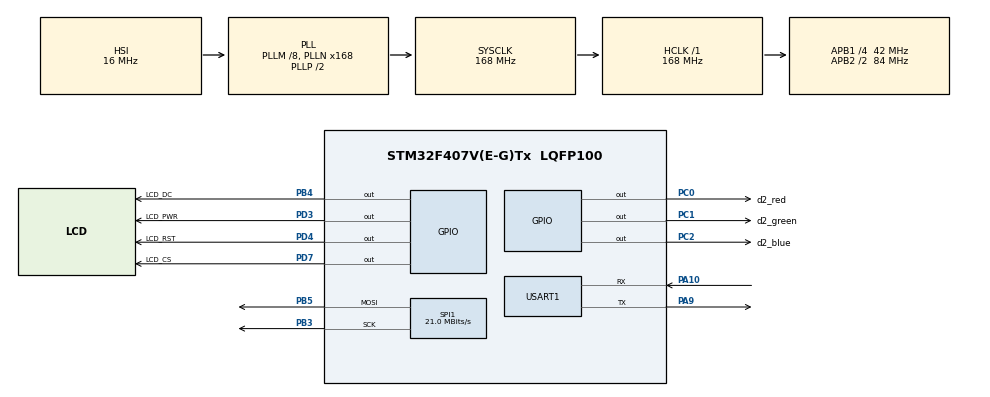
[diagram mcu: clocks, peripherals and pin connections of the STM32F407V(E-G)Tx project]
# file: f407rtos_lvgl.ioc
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Dma.Request0=USART1_RX
Dma.Request1=USART1_TX
Dma.USART1_RX.0.Direction=DMA_PERIPH_TO_MEMORY
Dma.USART1_RX.0.FIFOMode=DMA_FIFOMODE_DISABLE
Dma.USART1_RX.0.Instance=DMA2_Stream2
Dma.USART1_RX.0.MemDataAlignment=DMA_MDATAALIGN_BYTE
Dma.USART1_RX.0.MemInc=DMA_MINC_ENABLE
Dma.USART1_RX.0.Mode=DMA_NORMAL
Dma.USART1_RX.0.PeriphDataAlignment=DMA_PDATAALIGN_BYTE
Dma.USART1_RX.0.PeriphInc=DMA_PINC_DISABLE
Dma.USART1_RX.0.Priority=DMA_PRIORITY_LOW
Dma.USART1_TX.1.Direction=DMA_MEMORY_TO_PERIPH
Dma.USART1_TX.1.FIFOMode=DMA_FIFOMODE_DISABLE
Dma.USART1_TX.1.Instance=DMA2_Stream7
Dma.USART1_TX.1.MemDataAlignment=DMA_MDATAALIGN_BYTE
Dma.USART1_TX.1.MemInc=DMA_MINC_ENABLE
Dma.USART1_TX.1.Mode=DMA_NORMAL
Dma.USART1_TX.1.PeriphDataAlignment=DMA_PDATAALIGN_BYTE
Dma.USART1_TX.1.PeriphInc=DMA_PINC_DISABLE
Dma.USART1_TX.1.Priority=DMA_PRIORITY_LOW
IWDG.Prescaler=IWDG_PRESCALER_64
IWDG.Reload=1000
Mcu.Family=STM32F4
Mcu.Name=STM32F407V(E-G)Tx
Mcu.Package=LQFP100
NVIC.DMA2_Stream2_IRQn=true\:6\:0\:true\:false\:true\:false\:true\:true
NVIC.DMA2_Stream7_IRQn=true\:8\:0\:true\:false\:true\:false\:true\:true
NVIC.PriorityGroup=NVIC_PRIORITYGROUP_4
NVIC.TIM2_IRQn=true\:0\:0\:false\:false\:true\:true\:true\:true
NVIC.USART1_IRQn=true\:6\:0\:true\:false\:true\:true\:true\:true
PA10.Mode=Asynchronous
PA10.Signal=USART1_RX
PA13.Mode=Serial_Wire
PA13.Signal=SYS_JTMS-SWDIO
PA14.Mode=Serial_Wire
PA14.Signal=SYS_JTCK-SWCLK
PA9.Mode=Asynchronous
PA9.Signal=USART1_TX
PB3.Mode=TX_Only_Simplex_Unidirect_Master
PB3.Signal=SPI1_SCK
PB4.GPIO_Label=LCD_DC
PB4.GPIO_PuPd=GPIO_NOPULL
PB4.GPIO_Speed=GPIO_SPEED_FREQ_VERY_HIGH
PB4.Signal=GPIO_Output
PB5.Mode=TX_Only_Simplex_Unidirect_Master
PB5.Signal=SPI1_MOSI
PC0.GPIO_Label=d2_red
PC0.GPIO_Speed=GPIO_SPEED_FREQ_LOW
PC0.PinState=GPIO_PIN_SET
PC0.Signal=GPIO_Output
PC1.GPIO_Label=d2_green
PC1.PinState=GPIO_PIN_SET
PC1.Signal=GPIO_Output
PC2.GPIO_Label=d2_blue
PC2.PinState=GPIO_PIN_SET
PC2.Signal=GPIO_Output
PD3.GPIO_Label=LCD_PWR
PD3.GPIO_Speed=GPIO_SPEED_FREQ_VERY_HIGH
PD3.Signal=GPIO_Output
PD4.GPIO_Label=LCD_RST
PD4.GPIO_Speed=GPIO_SPEED_FREQ_VERY_HIGH
PD4.PinState=GPIO_PIN_SET
PD4.Signal=GPIO_Output
PD7.GPIO_Label=LCD_CS
PD7.GPIO_Speed=GPIO_SPEED_FREQ_VERY_HIGH
PD7.PinState=GPIO_PIN_SET
PD7.Signal=GPIO_Output
PH0-OSC_IN.Mode=HSE-External-Oscillator
PH0-OSC_IN.Signal=RCC_OSC_IN
PH1-OSC_OUT.Mode=HSE-External-Oscillator
PH1-OSC_OUT.Signal=RCC_OSC_OUT
ProjectManager.HeapSize=0x200
ProjectManager.StackSize=0x400
ProjectManager.TargetToolchain=CMake
RCC.48MHZClocksFreq_Value=84000000
RCC.AHBFreq_Value=168000000
RCC.APB1CLKDivider=RCC_HCLK_DIV4
RCC.APB1Freq_Value=42000000
RCC.APB1TimFreq_Value=84000000
RCC.APB2CLKDivider=RCC_HCLK_DIV2
RCC.APB2Freq_Value=84000000
RCC.APB2TimFreq_Value=168000000
RCC.CortexFreq_Value=168000000
RCC.HCLKFreq_Value=168000000
RCC.HSE_VALUE=25000000
RCC.HSI_VALUE=16000000
RCC.LSE_VALUE=32768
RCC.PLLM=8
RCC.PLLN=168
RCC.SYSCLKFreq_VALUE=168000000
RCC.SYSCLKSource=RCC_SYSCLKSOURCE_PLLCLK
RCC.VCOOutputFreq_Value=336000000
SPI1.BaudRatePrescaler=SPI_BAUDRATEPRESCALER_4
SPI1.CalculateBaudRate=21.0 MBits/s
SPI1.Direction=SPI_DIRECTION_2LINES
SPI1.Mode=SPI_MODE_MASTER
SPI1.VirtualType=VM_MASTER
TIM2.Period=99
TIM2.Prescaler=83
USART1.VirtualMode=VM_ASYNC
VP_IWDG_VS_IWDG.Mode=IWDG_Activate
VP_TIM2_VS_ClockSourceINT.Mode=Internal
board=custom

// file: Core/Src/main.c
/* USER CODE BEGIN Header */
/**
  ******************************************************************************
  * @file           : main.c
  * @brief          : Main program body
  ******************************************************************************
  * @attention
  *
  * Copyright (c) 2026 STMicroelectronics.
  * All rights reserved.
  *
  * This software is licensed under terms that can be found in the LICENSE file
  * in the root directory of this software component.
  * If no LICENSE file comes with this software, it is provided AS-IS.
  *
  ******************************************************************************
  */
/* USER CODE END Header */
#include "main.h"
#include "dma.h"
#include "iwdg.h"
#include "spi.h"
#include "tim.h"
#include "usart.h"
#include "gpio.h"

/* USER CODE BEGIN Includes */
#include "lcd.h"
#include "FreeRTOS.h"
#include "task.h"
#include "app.h"
#include "bsp_uart.h"
/* USER CODE END Includes */

/* USER CODE BEGIN PV */
// static TaskHandle_t led_task_handle = NULL;

/* USER CODE END PV */

void SystemClock_Config(void);

int main(void)
{

  /* MCU Configuration--------------------------------------------------------*/

  /* Reset of all peripherals, Initializes the Flash interface and the Systick. */
  HAL_Init();

  /* Configure the system clock */
  SystemClock_Config();

  /* Initialize all configured peripherals */
  MX_GPIO_Init();
  MX_DMA_Init();
  MX_SPI1_Init();
  MX_USART1_UART_Init();
  MX_TIM2_Init();
  MX_IWDG_Init();
  /* USER CODE BEGIN 2 */
  HAL_TIM_Base_Start_IT(&htim2);
  HAL_IWDG_Refresh(&hiwdg); // 上电先喂一口，争取时间
  /* USER CODE END 2 */

  /* Infinite loop */
  /* USER CODE BEGIN WHILE */

  App_Init();
  /* 启动调度器。这一句之后，CPU 交给 FreeRTOS 控制 */
  vTaskStartScheduler();

  /* 只有调度器启动失败（堆空间不够），才会执行到这里 */
  for (;;);

  while (1)
  {
    HAL_GPIO_TogglePin(d2_red_GPIO_Port, d2_red_Pin);
    HAL_Delay(500);

    /* USER CODE END WHILE */

  }
}

void SystemClock_Config(void)
{
  RCC_OscInitTypeDef RCC_OscInitStruct = {0};
  RCC_ClkInitTypeDef RCC_ClkInitStruct = {0};

  /** Configure the main internal regulator output voltage
  */
  __HAL_RCC_PWR_CLK_ENABLE();
  __HAL_PWR_VOLTAGESCALING_CONFIG(PWR_REGULATOR_VOLTAGE_SCALE1);

  /** Initializes the RCC Oscillators according to the specified parameters
  * in the RCC_OscInitTypeDef structure.
  */
  RCC_OscInitStruct.OscillatorType = RCC_OSCILLATORTYPE_HSI|RCC_OSCILLATORTYPE_LSI;
  RCC_OscInitStruct.HSIState = RCC_HSI_ON;
  RCC_OscInitStruct.HSICalibrationValue = RCC_HSICALIBRATION_DEFAULT;
  RCC_OscInitStruct.LSIState = RCC_LSI_ON;
  RCC_OscInitStruct.PLL.PLLState = RCC_PLL_ON;
  RCC_OscInitStruct.PLL.PLLSource = RCC_PLLSOURCE_HSI;
  RCC_OscInitStruct.PLL.PLLM = 8;
  RCC_OscInitStruct.PLL.PLLN = 168;
  RCC_OscInitStruct.PLL.PLLP = RCC_PLLP_DIV2;
  RCC_OscInitStruct.PLL.PLLQ = 4;
  if (HAL_RCC_OscConfig(&RCC_OscInitStruct) != HAL_OK)
  {
    Error_Handler();
  }

  /** Initializes the CPU, AHB and APB buses clocks
  */
  RCC_ClkInitStruct.ClockType = RCC_CLOCKTYPE_HCLK|RCC_CLOCKTYPE_SYSCLK
                              |RCC_CLOCKTYPE_PCLK1|RCC_CLOCKTYPE_PCLK2;
  RCC_ClkInitStruct.SYSCLKSource = RCC_SYSCLKSOURCE_PLLCLK;
  RCC_ClkInitStruct.AHBCLKDivider = RCC_SYSCLK_DIV1;
  RCC_ClkInitStruct.APB1CLKDivider = RCC_HCLK_DIV4;
  RCC_ClkInitStruct.APB2CLKDivider = RCC_HCLK_DIV2;

  if (HAL_RCC_ClockConfig(&RCC_ClkInitStruct, FLASH_LATENCY_5) != HAL_OK)
  {
    Error_Handler();
  }
}

void Error_Handler(void)
{
  __disable_irq();
  while (1)
  {
  }
}
